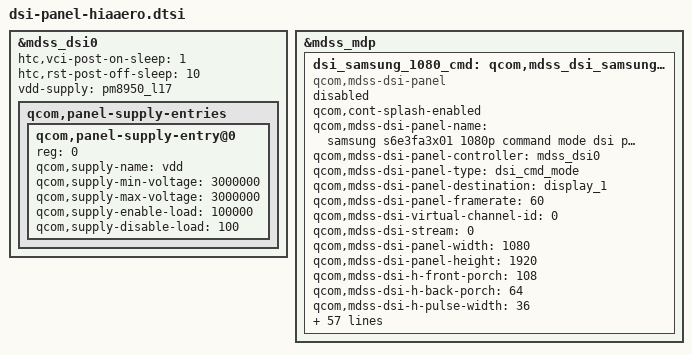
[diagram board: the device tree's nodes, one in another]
&mdss_dsi0 {
	htc,vci-post-on-sleep = <1>;

	htc,rst-post-off-sleep = <10>;

	vdd-supply = <&pm8950_l17>;
	qcom,panel-supply-entries {
		#address-cells = <1>;
		#size-cells = <0>;
		qcom,panel-supply-entry@0 {
			reg = <0>;
			qcom,supply-name = "vdd";
			qcom,supply-min-voltage = <3000000>;
			qcom,supply-max-voltage = <3000000>;
			qcom,supply-enable-load = <100000>;
			qcom,supply-disable-load = <100>;
		};
  };
};

&mdss_mdp {
	  dsi_samsung_1080_cmd: qcom,mdss_dsi_samsung_s6e3fa3x01_1080p_cmd{
		compatible = "qcom,mdss-dsi-panel";
		qcom,cont-splash-enabled;
		status = "disable";
		qcom,mdss-dsi-panel-name = "samsung s6e3fa3x01 1080p command mode dsi panel";
		qcom,mdss-dsi-panel-controller = <&mdss_dsi0>;
		qcom,mdss-dsi-panel-type = "dsi_cmd_mode";
		qcom,mdss-dsi-panel-destination = "display_1";
		qcom,mdss-dsi-panel-framerate = <60>;
		qcom,mdss-dsi-virtual-channel-id = <0>;
		qcom,mdss-dsi-stream = <0>;
		qcom,mdss-dsi-panel-width = <1080>;
		qcom,mdss-dsi-panel-height = <1920>;
		qcom,mdss-dsi-h-front-porch = <108>;
		qcom,mdss-dsi-h-back-porch = <64>;
		qcom,mdss-dsi-h-pulse-width = <36>;
		qcom,mdss-dsi-h-sync-skew = <0>;
		qcom,mdss-dsi-v-back-porch = <9>;
		qcom,mdss-dsi-v-front-porch = <7>;
		qcom,mdss-dsi-v-pulse-width = <2>;
		qcom,mdss-dsi-h-left-border = <0>;
		qcom,mdss-dsi-h-right-border = <0>;
		qcom,mdss-dsi-v-top-border = <0>;
		qcom,mdss-dsi-v-bottom-border = <0>;
		qcom,mdss-dsi-bpp = <24>;
		qcom,mdss-dsi-color-order = "rgb_swap_rgb";
		qcom,mdss-dsi-underflow-color = <0xFF>;
		qcom,mdss-dsi-border-color = <0>;
		qcom,mdss-dsi-te-pin-select = <1>;
		qcom,mdss-dsi-te-dcs-command = <1>;
		qcom,mdss-dsi-te-check-enable;
		qcom,mdss-dsi-te-using-te-pin;
		htc-fmt,mdss-dsi-on-command =
			"DTYPE_DCS_WRITE1", <20>, <2>, [11 00],
			"DTYPE_DCS_WRITE1", <0>, <2>, [35 00],
			"DTYPE_GEN_LWRITE", <0>, <3>, [FC 5A 5A],
			"DTYPE_DCS_WRITE1", <0>, <2>, [B0 1E],
			"DTYPE_DCS_WRITE1", <0>, <2>, [FD 9E],
			"DTYPE_GEN_LWRITE", <0>, <3>, [FC A5 A5],
			"DTYPE_DCS_WRITE1", <80>, <2>, [53 20],
			"DTYPE_DCS_WRITE" , <50>, <2>, [29 00];/* LCD Display on */
		htc-fmt,mdss-dsi-off-command =
			"DTYPE_DCS_WRITE", <11>, <2>, [28 00],
			"DTYPE_DCS_WRITE", <150>, <2>, [10 00];
		qcom,mdss-dsi-on-command-state = "dsi_lp_mode";
		qcom,mdss-dsi-off-command-state = "dsi_hs_mode";
		qcom,mdss-dsi-h-sync-pulse = <0>;
		qcom,mdss-dsi-traffic-mode = "non_burst_sync_event";
		qcom,mdss-dsi-bllp-eof-power-mode;
		qcom,mdss-dsi-lane-map = "lane_map_0123";
		qcom,mdss-dsi-bllp-power-mode;
		qcom,mdss-dsi-lane-0-state;
		qcom,mdss-dsi-lane-1-state;
		qcom,mdss-dsi-lane-2-state;
		qcom,mdss-dsi-lane-3-state;
		qcom,mdss-dsi-panel-timings = [EE 38 26 00 68 6E 2A 3C 2C 03 04 00];
		qcom,mdss-dsi-t-clk-post = <0x02>;
		qcom,mdss-dsi-t-clk-pre = <0x2B>;
		qcom,mdss-dsi-bl-min-level = <1>;
		qcom,mdss-dsi-bl-max-level = <255>;
		qcom,mdss-dsi-dma-trigger = "trigger_sw";
		qcom,mdss-dsi-mdp-trigger = "none";
		qcom,mdss-dsi-bl-pmic-control-type = "bl_ctrl_dcs";
		qcom,mdss-dsi-reset-sequence = <1 2>, <0 1>, <1 10>;
		htc-fmt,dimming-on-cmds = "DTYPE_DCS_WRITE1", <0>, <2>, [53 28];
		htc-fmt,dimming-off-cmds = "DTYPE_DCS_LWRITE", <0>, <2>, [53 20];
		htc-fmt,burst-on-cmds = "DTYPE_DCS_LWRITE", <0>, <2>, [53 e8];
		htc-fmt,burst-off-cmds = "DTYPE_DCS_LWRITE", <0>, <2>, [53 28];
		htc,burst-on-level = <11>;
		htc,burst-off-level = <8>;
		qcom,mdss-dsi-default-command-state = "dsi_hs_mode";
		qcom,mdss-pan-physical-width-dimension = <62>;
		qcom,mdss-pan-physical-height-dimension = <110>;
		htc,mdss-shrink-pwm = <7 87 255>;
		qcom,mdss-dsi-lp11-init;
		htc,mdss-camera-blk = <181>;
		htc,blk_pending_display_on;
		htc,disable-backlight-when-flashlight;
	};
};

